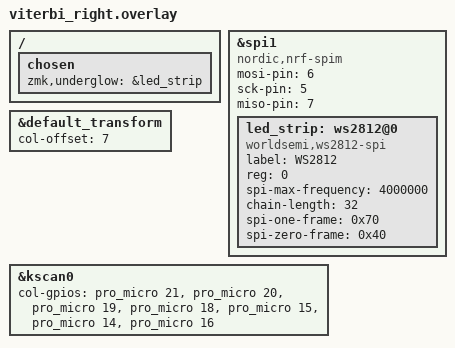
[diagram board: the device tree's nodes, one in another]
#include "viterbi.dtsi"
#include <dt-bindings/zmk/rgb.h>

&spi1 {
  compatible = "nordic,nrf-spim";
  status = "okay";
  mosi-pin = <6>;
  // Unused pins, needed for SPI definition, but not used by the ws2812 driver itself.
  sck-pin = <5>;
  miso-pin = <7>;

  led_strip: ws2812@0 {
    compatible = "worldsemi,ws2812-spi";
    label = "WS2812";

    /* SPI */
    reg = <0>; /* ignored, but necessary for SPI bindings */
    spi-max-frequency = <4000000>;

    /* WS2812 */
    chain-length = <32>; /* number of LEDs */
    spi-one-frame = <0x70>;
    spi-zero-frame = <0x40>;
  };
};

/ {
  chosen {
    zmk,underglow = &led_strip;
  };
};


&default_transform { 
    col-offset = <7>;
};

&kscan0 {
    col-gpios
        = <&pro_micro 21 GPIO_ACTIVE_HIGH>
        , <&pro_micro 20 GPIO_ACTIVE_HIGH>
        , <&pro_micro 19 GPIO_ACTIVE_HIGH>
        , <&pro_micro 18 GPIO_ACTIVE_HIGH>
        , <&pro_micro 15 GPIO_ACTIVE_HIGH>
        , <&pro_micro 14 GPIO_ACTIVE_HIGH>
        , <&pro_micro 16 GPIO_ACTIVE_HIGH>
        ;
};
